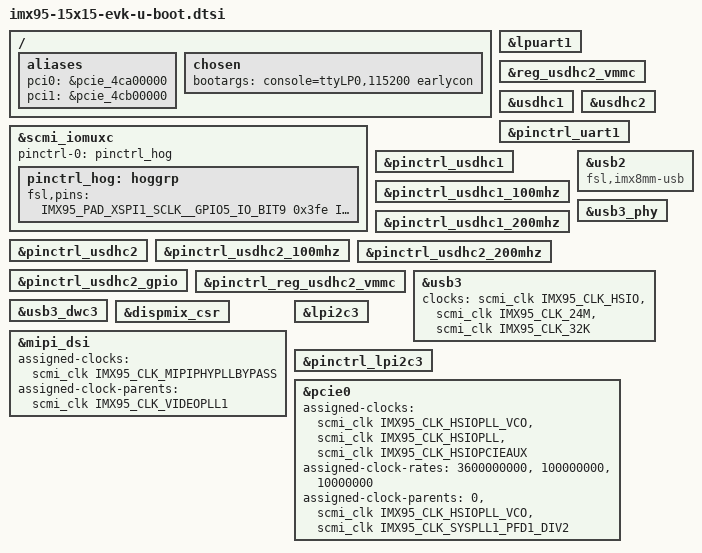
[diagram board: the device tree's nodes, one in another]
// SPDX-License-Identifier: GPL-2.0+
/*
 * Copyright 2024 NXP
 */

/ {
	aliases {
		pci0 = &pcie_4ca00000;
		pci1 = &pcie_4cb00000;
	};

	chosen {
		bootargs = "console=ttyLP0,115200 earlycon";
	};
};

&scmi_iomuxc {
	pinctrl-names = "default";
	pinctrl-0 = <&pinctrl_hog>;

	pinctrl_hog: hoggrp {
		bootph-all;
		bootph-pre-ram;

		fsl,pins = <
			IMX95_PAD_XSPI1_SCLK__GPIO5_IO_BIT9			0x3fe
			IMX95_PAD_CCM_CLKO1__GPIO3_IO_BIT26			0x30e
			IMX95_PAD_CCM_CLKO2__GPIO3_IO_BIT27			0x30e
		>;
	};
};

&lpuart1 {
	bootph-pre-ram;
};

&reg_usdhc2_vmmc {
	bootph-pre-ram;
};

&usdhc1 {
	bootph-pre-ram;
};

&usdhc2 {
	bootph-pre-ram;
};

&pinctrl_uart1 {
	bootph-pre-ram;
};

&pinctrl_usdhc1 {
	bootph-pre-ram;
};

&pinctrl_usdhc1_100mhz {
	bootph-pre-ram;
};

&pinctrl_usdhc1_200mhz {
	bootph-pre-ram;
};

&pinctrl_usdhc2 {
	bootph-pre-ram;
};

&pinctrl_usdhc2_100mhz {
	bootph-pre-ram;
};

&pinctrl_usdhc2_200mhz {
	bootph-pre-ram;
};

&pinctrl_usdhc2_gpio {
	bootph-pre-ram;
};

&pinctrl_reg_usdhc2_vmmc {
	bootph-pre-ram;
};

&usb2 {
	compatible = "fsl,imx8mm-usb", "fsl,imx7d-usb";
	/delete-property/power-domains;
};

&usb3_phy {
	bootph-pre-ram;
};

&usb3 {
	clocks = <&scmi_clk IMX95_CLK_HSIO>,
			 <&scmi_clk IMX95_CLK_24M>,
			 <&scmi_clk IMX95_CLK_32K>;
	clock-names = "hsio", "ref", "suspend";

	/delete-property/power-domains;
	bootph-pre-ram;
};

&usb3_dwc3 {
	bootph-pre-ram;
};

&dispmix_csr {
	/delete-property/ assigned-clocks;
	/delete-property/ assigned-clock-rates;
	/delete-property/ assigned-clock-parents;
};

&mipi_dsi {
	assigned-clocks = <&scmi_clk IMX95_CLK_MIPIPHYPLLBYPASS>;
	assigned-clock-parents = <&scmi_clk IMX95_CLK_VIDEOPLL1>;
};


&lpi2c3 {
	bootph-some-ram;
};

&pinctrl_lpi2c3 {
	bootph-some-ram;
};

&pcie0 {
	assigned-clocks =<&scmi_clk IMX95_CLK_HSIOPLL_VCO>,
			 <&scmi_clk IMX95_CLK_HSIOPLL>,
			 <&scmi_clk IMX95_CLK_HSIOPCIEAUX>;
	assigned-clock-rates = <3600000000>, <100000000>, <10000000>;
	assigned-clock-parents = <0>, <&scmi_clk IMX95_CLK_HSIOPLL_VCO>,
				 <&scmi_clk IMX95_CLK_SYSPLL1_PFD1_DIV2>;
};
